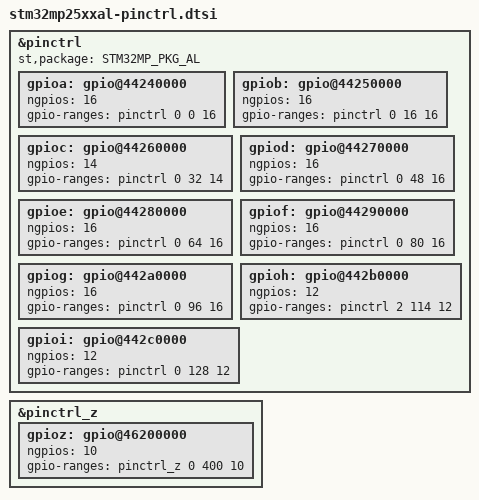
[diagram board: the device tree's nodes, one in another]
// SPDX-License-Identifier: (GPL-2.0-or-later OR BSD-3-Clause)
/*
 * Copyright (C) STMicroelectronics 2023 - All Rights Reserved
 * Author: Alexandre Torgue <alexandre.torgue@foss.st.com> for STMicroelectronics.
 */

&pinctrl {
	st,package = <STM32MP_PKG_AL>;

	gpioa: gpio@44240000 {
		status = "okay";
		ngpios = <16>;
		gpio-ranges = <&pinctrl 0 0 16>;
	};

	gpiob: gpio@44250000 {
		status = "okay";
		ngpios = <16>;
		gpio-ranges = <&pinctrl 0 16 16>;
	};

	gpioc: gpio@44260000 {
		status = "okay";
		ngpios = <14>;
		gpio-ranges = <&pinctrl 0 32 14>;
	};

	gpiod: gpio@44270000 {
		status = "okay";
		ngpios = <16>;
		gpio-ranges = <&pinctrl 0 48 16>;
	};

	gpioe: gpio@44280000 {
		status = "okay";
		ngpios = <16>;
		gpio-ranges = <&pinctrl 0 64 16>;
	};

	gpiof: gpio@44290000 {
		status = "okay";
		ngpios = <16>;
		gpio-ranges = <&pinctrl 0 80 16>;
	};

	gpiog: gpio@442a0000 {
		status = "okay";
		ngpios = <16>;
		gpio-ranges = <&pinctrl 0 96 16>;
	};

	gpioh: gpio@442b0000 {
		status = "okay";
		ngpios = <12>;
		gpio-ranges = <&pinctrl 2 114 12>;
	};

	gpioi: gpio@442c0000 {
		status = "okay";
		ngpios = <12>;
		gpio-ranges = <&pinctrl 0 128 12>;
	};
};

&pinctrl_z {
	gpioz: gpio@46200000 {
		status = "okay";
		ngpios = <10>;
		gpio-ranges = <&pinctrl_z 0 400 10>;
	};
};
